AUTOSAR XML (schema 00044)
package /ComponentTypes
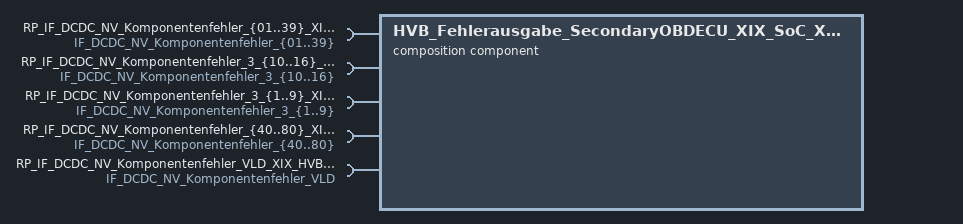
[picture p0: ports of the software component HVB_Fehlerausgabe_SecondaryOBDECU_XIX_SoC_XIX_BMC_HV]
  composition sw component type HVB_Fehlerausgabe_SecondaryOBDECU_XIX_SoC_XIX_BMC_HV
    97 x require port:
      RP_IF_DCDC_NV_Komponentenfehler_{01..39}_XIX_HVB_Fehlerausgabe_SecondaryOBDECU_XIX_SoC_XIX_BMC_HV: nonqueued-receiver-com-spec=DE_DCDC_NV_Komponentenfehler_{01..39}, required-interface=IF_DCDC_NV_Komponentenfehler_{01..39}
      RP_IF_DCDC_NV_Komponentenfehler_3_{10..16}_XIX_HVB_Fehlerausgabe_SecondaryOBDECU_XIX_SoC_XIX_BMC_HV: nonqueued-receiver-com-spec=DE_DCDC_NV_Komponentenfehler_3_{10..16}, required-interface=IF_DCDC_NV_Komponentenfehler_3_{10..16}
      RP_IF_DCDC_NV_Komponentenfehler_3_{1..9}_XIX_HVB_Fehlerausgabe_SecondaryOBDECU_XIX_SoC_XIX_BMC_HV: nonqueued-receiver-com-spec=DE_DCDC_NV_Komponentenfehler_3_{1..9}, required-interface=IF_DCDC_NV_Komponentenfehler_3_{1..9}
      RP_IF_DCDC_NV_Komponentenfehler_{40..80}_XIX_HVB_Fehlerausgabe_SecondaryOBDECU_XIX_SoC_XIX_BMC_HV: nonqueued-receiver-com-spec=DE_DCDC_NV_Komponentenfehler_{40..80}, required-interface=IF_DCDC_NV_Komponentenfehler_{40..80}
      RP_IF_DCDC_NV_Komponentenfehler_VLD_XIX_HVB_Fehlerausgabe_SecondaryOBDECU_XIX_SoC_XIX_BMC_HV: nonqueued-receiver-com-spec=DE_DCDC_NV_Komponentenfehler_VLD, required-interface=IF_DCDC_NV_Komponentenfehler_VLD
